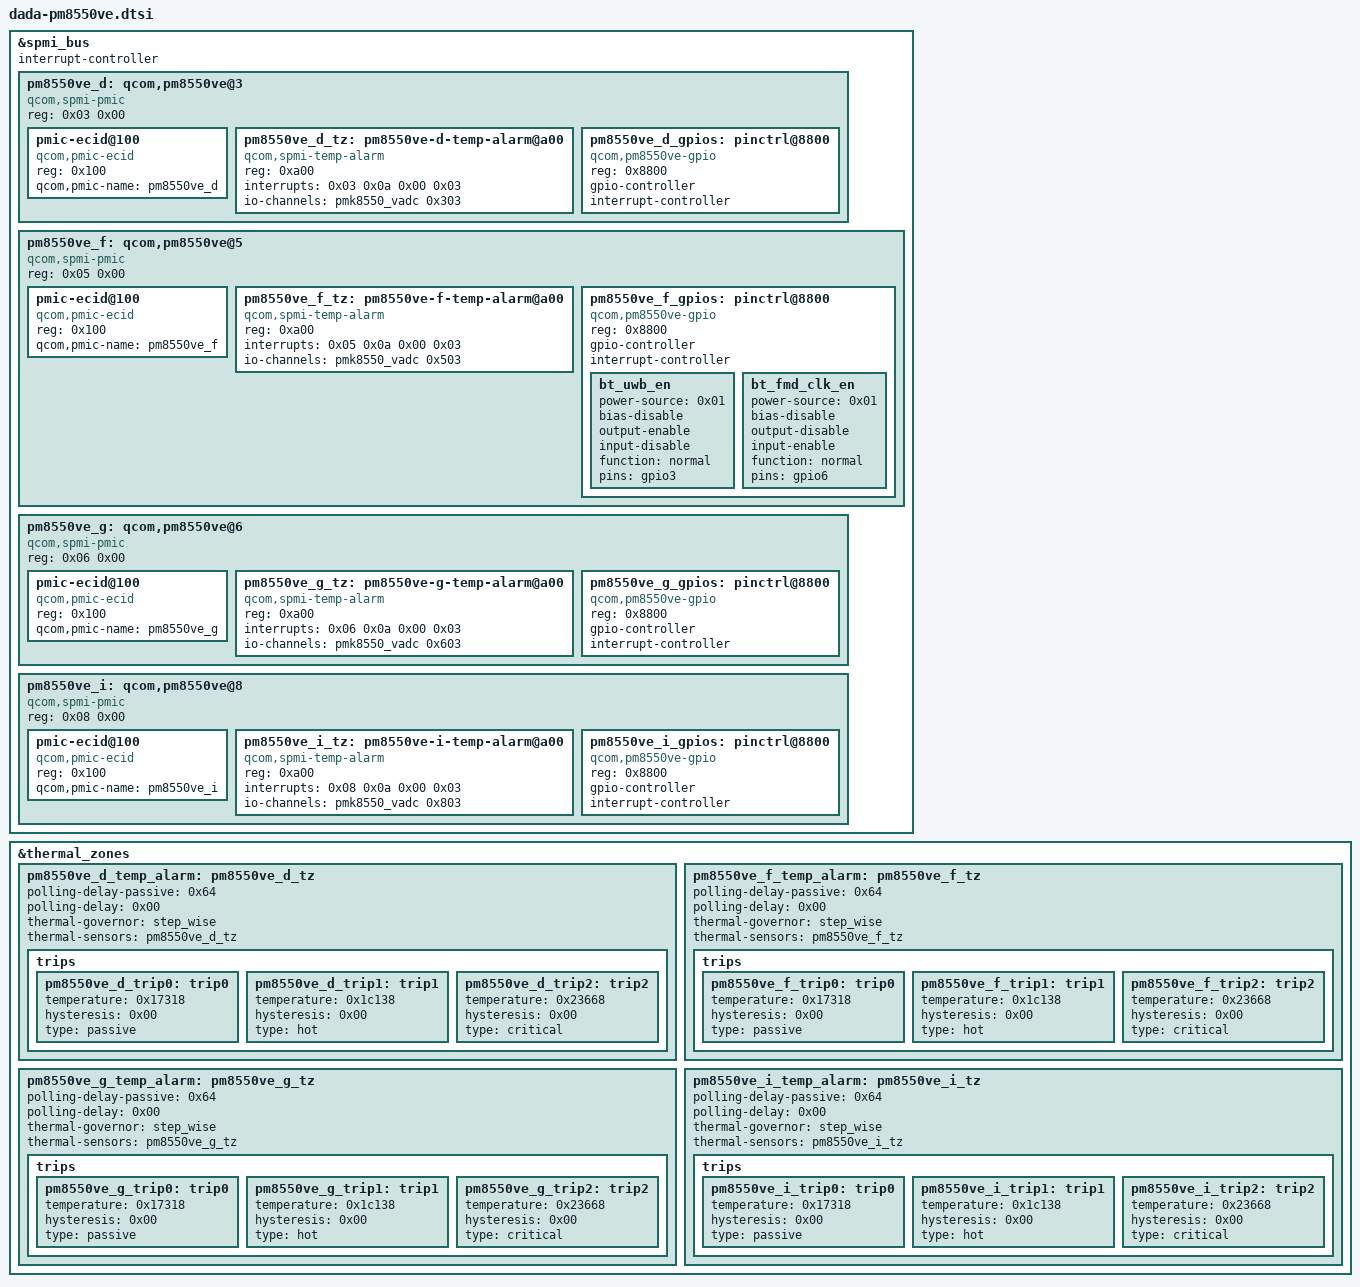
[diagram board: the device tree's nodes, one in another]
// SPDX-License-Identifier: BSD-3-Clause
/*
 * Copyright (c) 2023-2024 Qualcomm Innovation Center, Inc. All rights reserved.
 * Copyright (c) 2025 The LineageOS Project
 */

&spmi_bus {
	#address-cells = <0x02>;
	#size-cells = <0x00>;
	interrupt-controller;
	#interrupt-cells = <0x04>;

	pm8550ve_d: qcom,pm8550ve@3 {
		compatible = "qcom,spmi-pmic";
		reg = <0x03 0x00>;
		#address-cells = <0x01>;
		#size-cells = <0x00>;
		status = "ok";

		pmic-ecid@100 {
			compatible = "qcom,pmic-ecid";
			reg = <0x100>;
			qcom,pmic-name = "pm8550ve_d";
		};

		pm8550ve_d_tz: pm8550ve-d-temp-alarm@a00 {
			compatible = "qcom,spmi-temp-alarm";
			reg = <0xa00>;
			interrupts = <0x03 0x0a 0x00 0x03>;
			#thermal-sensor-cells = <0x00>;
			io-channels = <&pmk8550_vadc 0x303>;
			io-channel-names = "thermal";
		};

		pm8550ve_d_gpios: pinctrl@8800 {
			compatible = "qcom,pm8550ve-gpio";
			reg = <0x8800>;
			gpio-controller;
			#gpio-cells = <0x02>;
			interrupt-controller;
			#interrupt-cells = <0x02>;
		};
	};

	pm8550ve_f: qcom,pm8550ve@5 {
		compatible = "qcom,spmi-pmic";
		reg = <0x05 0x00>;
		#address-cells = <0x01>;
		#size-cells = <0x00>;
		status = "ok";

		pmic-ecid@100 {
			compatible = "qcom,pmic-ecid";
			reg = <0x100>;
			qcom,pmic-name = "pm8550ve_f";
		};

		pm8550ve_f_tz: pm8550ve-f-temp-alarm@a00 {
			compatible = "qcom,spmi-temp-alarm";
			reg = <0xa00>;
			interrupts = <0x05 0x0a 0x00 0x03>;
			#thermal-sensor-cells = <0x00>;
			io-channels = <&pmk8550_vadc 0x503>;
			io-channel-names = "thermal";
		};

		pm8550ve_f_gpios: pinctrl@8800 {
			compatible = "qcom,pm8550ve-gpio";
			reg = <0x8800>;
			gpio-controller;
			#gpio-cells = <0x02>;
			interrupt-controller;
			#interrupt-cells = <0x02>;

			bt_uwb_en: bt_uwb_en {
				power-source = <0x01>;
				bias-disable;
				output-enable;
				input-disable;
				function = "normal";
				pins = "gpio3";
			};

			bt_fmd_clk_en: bt_fmd_clk_en {
				power-source = <0x01>;
				bias-disable;
				output-disable;
				input-enable;
				function = "normal";
				pins = "gpio6";
			};
		};
	};

	pm8550ve_g: qcom,pm8550ve@6 {
		compatible = "qcom,spmi-pmic";
		reg = <0x06 0x00>;
		#address-cells = <0x01>;
		#size-cells = <0x00>;
		status = "ok";

		pmic-ecid@100 {
			compatible = "qcom,pmic-ecid";
			reg = <0x100>;
			qcom,pmic-name = "pm8550ve_g";
		};

		pm8550ve_g_tz: pm8550ve-g-temp-alarm@a00 {
			compatible = "qcom,spmi-temp-alarm";
			reg = <0xa00>;
			interrupts = <0x06 0x0a 0x00 0x03>;
			#thermal-sensor-cells = <0x00>;
			io-channels = <&pmk8550_vadc 0x603>;
			io-channel-names = "thermal";
		};

		pm8550ve_g_gpios: pinctrl@8800 {
			compatible = "qcom,pm8550ve-gpio";
			reg = <0x8800>;
			gpio-controller;
			#gpio-cells = <0x02>;
			interrupt-controller;
			#interrupt-cells = <0x02>;
		};
	};

	pm8550ve_i: qcom,pm8550ve@8 {
		compatible = "qcom,spmi-pmic";
		reg = <0x08 0x00>;
		#address-cells = <0x01>;
		#size-cells = <0x00>;
		status = "ok";

		pmic-ecid@100 {
			compatible = "qcom,pmic-ecid";
			reg = <0x100>;
			qcom,pmic-name = "pm8550ve_i";
		};

		pm8550ve_i_tz: pm8550ve-i-temp-alarm@a00 {
			compatible = "qcom,spmi-temp-alarm";
			reg = <0xa00>;
			interrupts = <0x08 0x0a 0x00 0x03>;
			#thermal-sensor-cells = <0x00>;
			io-channels = <&pmk8550_vadc 0x803>;
			io-channel-names = "thermal";
		};

		pm8550ve_i_gpios: pinctrl@8800 {
			compatible = "qcom,pm8550ve-gpio";
			reg = <0x8800>;
			gpio-controller;
			#gpio-cells = <0x02>;
			interrupt-controller;
			#interrupt-cells = <0x02>;
		};
	};
};

&thermal_zones {
	pm8550ve_d_temp_alarm: pm8550ve_d_tz {
		polling-delay-passive = <0x64>;
		polling-delay = <0x00>;
		thermal-governor = "step_wise";
		thermal-sensors = <&pm8550ve_d_tz>;
		status = "ok";

		trips {

			pm8550ve_d_trip0: trip0 {
				temperature = <0x17318>;
				hysteresis = <0x00>;
				type = "passive";
			};

			pm8550ve_d_trip1: trip1 {
				temperature = <0x1c138>;
				hysteresis = <0x00>;
				type = "hot";
			};

			pm8550ve_d_trip2: trip2 {
				temperature = <0x23668>;
				hysteresis = <0x00>;
				type = "critical";
			};
		};
	};

	pm8550ve_f_temp_alarm: pm8550ve_f_tz {
		polling-delay-passive = <0x64>;
		polling-delay = <0x00>;
		thermal-governor = "step_wise";
		thermal-sensors = <&pm8550ve_f_tz>;
		status = "ok";

		trips {

			pm8550ve_f_trip0: trip0 {
				temperature = <0x17318>;
				hysteresis = <0x00>;
				type = "passive";
			};

			pm8550ve_f_trip1: trip1 {
				temperature = <0x1c138>;
				hysteresis = <0x00>;
				type = "hot";
			};

			pm8550ve_f_trip2: trip2 {
				temperature = <0x23668>;
				hysteresis = <0x00>;
				type = "critical";
			};
		};
	};

	pm8550ve_g_temp_alarm: pm8550ve_g_tz {
		polling-delay-passive = <0x64>;
		polling-delay = <0x00>;
		thermal-governor = "step_wise";
		thermal-sensors = <&pm8550ve_g_tz>;
		status = "ok";

		trips {

			pm8550ve_g_trip0: trip0 {
				temperature = <0x17318>;
				hysteresis = <0x00>;
				type = "passive";
			};

			pm8550ve_g_trip1: trip1 {
				temperature = <0x1c138>;
				hysteresis = <0x00>;
				type = "hot";
			};

			pm8550ve_g_trip2: trip2 {
				temperature = <0x23668>;
				hysteresis = <0x00>;
				type = "critical";
			};
		};
	};

	pm8550ve_i_temp_alarm: pm8550ve_i_tz {
		polling-delay-passive = <0x64>;
		polling-delay = <0x00>;
		thermal-governor = "step_wise";
		thermal-sensors = <&pm8550ve_i_tz>;
		status = "ok";

		trips {

			pm8550ve_i_trip0: trip0 {
				temperature = <0x17318>;
				hysteresis = <0x00>;
				type = "passive";
			};

			pm8550ve_i_trip1: trip1 {
				temperature = <0x1c138>;
				hysteresis = <0x00>;
				type = "hot";
			};

			pm8550ve_i_trip2: trip2 {
				temperature = <0x23668>;
				hysteresis = <0x00>;
				type = "critical";
			};
		};
	};
};
